AUTOSAR XML (schema 314)
package /ComponentType
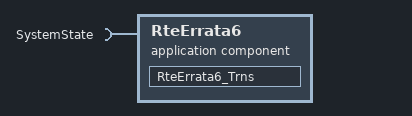
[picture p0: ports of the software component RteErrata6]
  application software component type RteErrata6  # This SWC contains definitions required to workaround Rte Generation errata following: 1) ESCAN00059438AN00059438 (corrected in Rte 2.22.00)
    require port SystemState: required-interface=SystemState
  internal behavior RteErrata6_InternalBehavior: component=RteErrata6, port-api-option{enable-take-address=false, indirect-api=false, port=SystemState}
    4 x mode switch event, all with start-on-event=RteErrata6_Trns, activation=ENTRY:
      MST_RteErrata6_Trns_0: mode=SystemState.Mode.WARMINIT
      MST_RteErrata6_Trns_1: mode=SystemState.Mode.OFF
      MST_RteErrata6_Trns_2: mode=SystemState.Mode.OPERATE
      MST_RteErrata6_Trns_3: mode=SystemState.Mode.DISABLE
    runnable RteErrata6_Trns
  swc implementation RteErrata6_Implementation: behavior=RteErrata6_InternalBehavior
    code-descriptors:
      code Code: type=SRC
